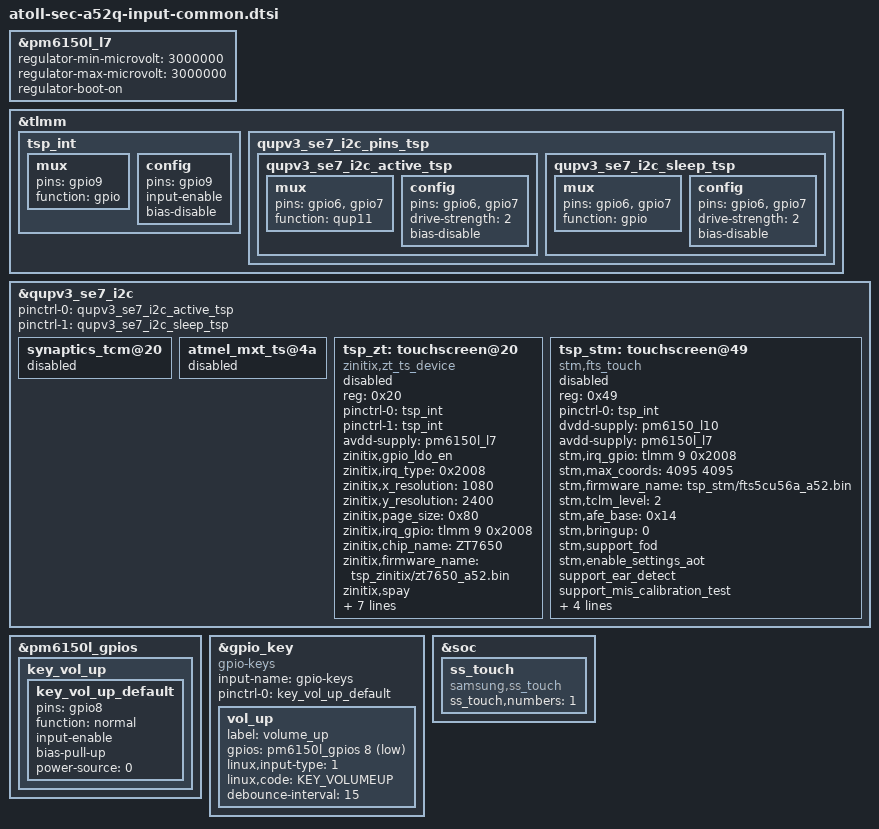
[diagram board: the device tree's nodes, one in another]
/* Copyright (c) 2016-2017, The Linux Foundation. All rights reserved.
 *
 * This program is free software; you can redistribute it and/or modify
 * it under the terms of the GNU General Public License version 2 and
 * only version 2 as published by the Free Software Foundation.
 *
 * This program is distributed in the hope that it will be useful,
 * but WITHOUT ANY WARRANTY; without even the implied warranty of
 * MERCHANTABILITY or FITNESS FOR A PARTICULAR PURPOSE.  See the
 * GNU General Public License for more details.
 */

#include <dt-bindings/input/input.h>
#include <dt-bindings/msm/msm-bus-ids.h>

&pm6150l_l7 {
	regulator-min-microvolt = <3000000>;
	regulator-max-microvolt = <3000000>;
	regulator-boot-on;
};

&tlmm {
	tsp_int: tsp_int {
		mux {
			pins = "gpio9";
			function = "gpio";
		};
		
		config {
			pins = "gpio9";
			input-enable;
			bias-disable;
		};
	};

	qupv3_se7_i2c_pins_tsp: qupv3_se7_i2c_pins_tsp {
		qupv3_se7_i2c_active_tsp: qupv3_se7_i2c_active_tsp {
			mux {
				pins = "gpio6", "gpio7";
				function = "qup11";
			};

			config {
				pins = "gpio6", "gpio7";
				drive-strength = <2>;
				bias-disable;
			};
		};

		qupv3_se7_i2c_sleep_tsp: qupv3_se7_i2c_sleep_tsp {
			mux {
				pins = "gpio6", "gpio7";
				function = "gpio";
			};

			config {
				pins = "gpio6", "gpio7";
				drive-strength = <2>;
				bias-disable;
			};
		};
	};
};

&qupv3_se7_i2c {
	status = "ok";
	pinctrl-names = "default", "sleep";
	pinctrl-0 = <&qupv3_se7_i2c_active_tsp>;
	pinctrl-1 = <&qupv3_se7_i2c_sleep_tsp>;

	synaptics_tcm@20 {
		status = "disabled";
	};
	atmel_mxt_ts@4a {
		status = "disabled";
	};

	tsp_zt: touchscreen@20 {
		status = "disabled";
		compatible = "zinitix,zt_ts_device";
		reg = <0x20>;
		pinctrl-names = "on_state", "off_state";
		pinctrl-0 = <&tsp_int>;
		pinctrl-1 = <&tsp_int>;
		avdd-supply = <&pm6150l_l7>;
		zinitix,gpio_ldo_en;
		zinitix,irq_type = <0x2008>;
		zinitix,x_resolution = <1080>;
		zinitix,y_resolution = <2400>;
		zinitix,page_size = <0x80>;
		zinitix,irq_gpio = <&tlmm 9 0x2008>;
		zinitix,chip_name = "ZT7650";
		zinitix,firmware_name = "tsp_zinitix/zt7650_a52.bin";
		zinitix,spay;
		zinitix,aod;
		zinitix,aot;
		zinitix,mis_cal_check;
		support_ear_detect_mode;
		support_dex_mode;
		zinitix,bringup = <0>;
//		zinitix,tclm_level = <0x2>;
//		zinitix,afe_base = <0xe>;
		zinitix,ss_touch_num = <0x1>;
	};

	tsp_stm: touchscreen@49 {
		status = "disabled";
		compatible = "stm,fts_touch";
		reg = <0x49>;
		pinctrl-names = "default";
		pinctrl-0 = <&tsp_int>;
		dvdd-supply = <&pm6150_l10>;
		avdd-supply = <&pm6150l_l7>;
		stm,irq_gpio = <&tlmm 9 0x2008>;
		stm,max_coords = <4095 4095>;
		stm,firmware_name = "tsp_stm/fts5cu56a_a52.bin";
		stm,tclm_level = <2>;
		stm,afe_base = <0x14>;
		stm,bringup = <0>;
		stm,support_fod;
		stm,enable_settings_aot;
		support_ear_detect;
		support_mis_calibration_test;
		support_dex_mode;
		support_open_short_test;
		support_sram_test;
//		support_hall_ic;
//		support_flex_mode;
		stm,ss_touch_num = <1>;
//		stm,hw_i2c_reset;
	};
};

/delete-node/&key_vol_up_default;
&pm6150l_gpios {
	key_vol_up {
		key_vol_up_default: key_vol_up_default {
			pins = "gpio8";
			function = "normal";
			input-enable;
			bias-pull-up;
			power-source = <0>;
		};
	};
};

/delete-node/&gpio_key;
&gpio_key {
	status = "okay";
	compatible = "gpio-keys";
	input-name = "gpio-keys";

	pinctrl-names = "default";
	pinctrl-0 = <&key_vol_up_default>;

	vol_up {
		label = "volume_up";
		gpios = <&pm6150l_gpios 8 0x1>;
		linux,input-type = <1>;
		linux,code = <KEY_VOLUMEUP>;
		debounce-interval = <15>;
	};
};

&soc {
	ss_touch {
		compatible = "samsung,ss_touch";
		ss_touch,numbers = <1>;
	};
};
